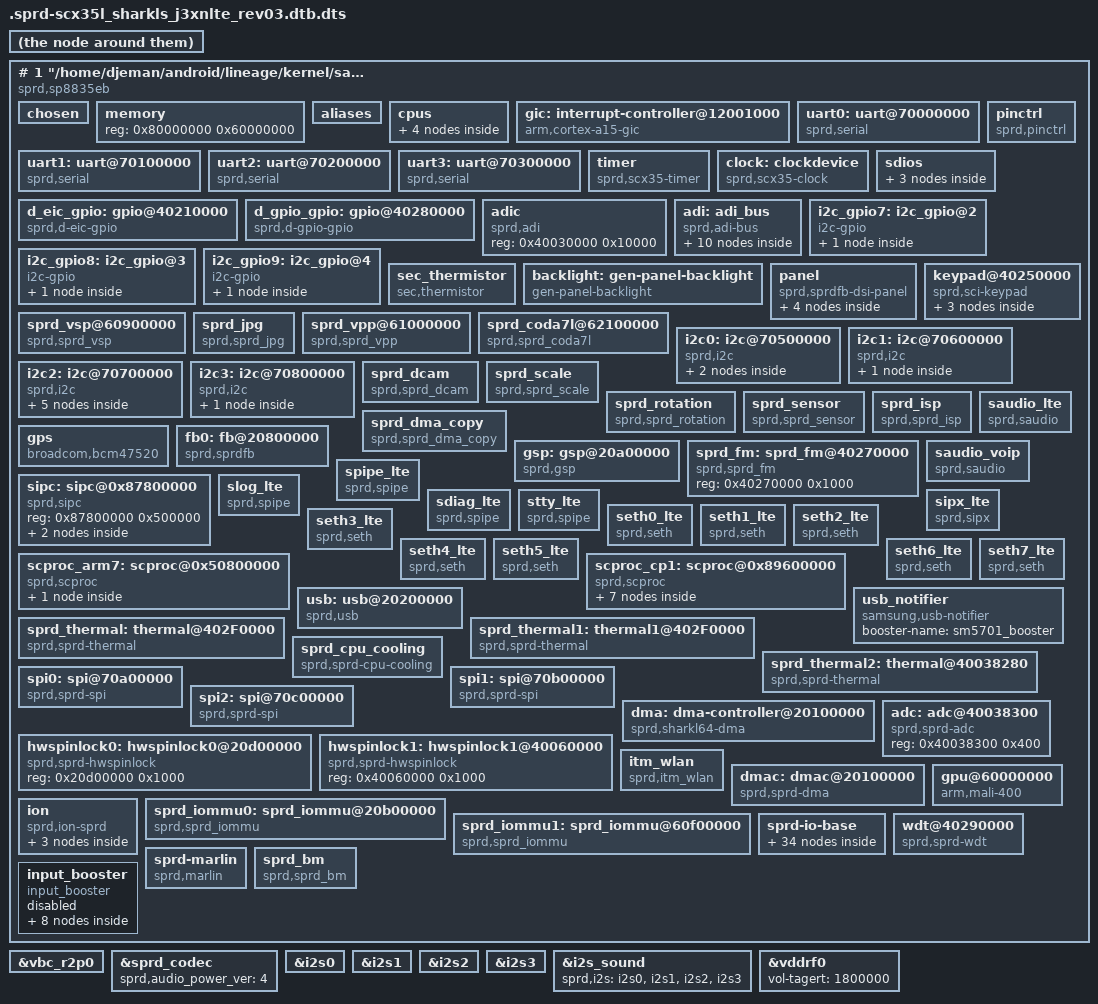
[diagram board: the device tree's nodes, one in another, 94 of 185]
# 1 "arch/arm/boot/dts/sprd-scx35l_sharkls_j3xnlte_rev03.dts"
# 1 "<command-line>"
# 1 "arch/arm/boot/dts/sprd-scx35l_sharkls_j3xnlte_rev03.dts"
# 9 "arch/arm/boot/dts/sprd-scx35l_sharkls_j3xnlte_rev03.dts"
/dts-v1/;


/memreserve/ 0x87800000 0x500000;


/memreserve/ 0x89600000 0x4280000;


/memreserve/ 0x9B23B000 0x3939000;

/memreserve/ 0x9EB74000 0xA8C000;


/memreserve/ 0x9F600000 0x708000;

/include/ "skeleton.dtsi"
/include/ "scx35l-sp9830iea-5m-clocks.dtsi"
/include/ "sc2723-regulators.dtsi"
/include/ "sprd-sound.dtsi"
/include/ "sprd-scx35l_batterydata_j3xlte_r00.dtsi"

# 1 "/home/djeman/android/lineage/kernel/samsung/j3xnlte/arch/arm/boot/dts/include/dt-bindings/gpio/gpio.h" 1
# 32 "arch/arm/boot/dts/sprd-scx35l_sharkls_j3xnlte_rev03.dts" 2
# 1 "/home/djeman/android/lineage/kernel/samsung/j3xnlte/arch/arm/boot/dts/include/dt-bindings/interrupt-controller/irq.h" 1
# 33 "arch/arm/boot/dts/sprd-scx35l_sharkls_j3xnlte_rev03.dts" 2

/ {
 model = "Spreadtrum SP8835EB board";
 compatible = "sprd,sp8835eb";
 sprd,sc-id = <9830 3 0x20000>;
 #address-cells = <1>;
 #size-cells = <1>;
 interrupt-parent = <&gic>;

 chosen {
  bootargs = "loglevel=1 init=/init root=/dev/ram0 rw";
  linux,initrd-start = <0x85500000>;
  linux,initrd-end = <0x855a3212>;
 };

 memory {
  device_type = "memory";
  reg = <0x80000000 0x60000000>;
 };

 aliases {
  serial0 = &uart0;
  serial1 = &uart1;
  serial2 = &uart2;
  serial3 = &uart3;
  i2c0 = &i2c0;
  i2c1 = &i2c1;
  i2c2 = &i2c2;
  i2c3 = &i2c3;
  lcd0 = &fb0;
  spi0 = &spi0;
  spi1 = &spi1;
  spi2 = &spi2;
  hwspinlock0 = &hwspinlock0;
  hwspinlock1 = &hwspinlock1;
  i2c_gpio7 = &i2c_gpio7;
  i2c_gpio8 = &i2c_gpio8;
  i2c_gpio9 = &i2c_gpio9;
 };

 cpus {
  #address-cells = <1>;
  #size-cells = <0>;

  cpu@f00 {
   device_type = "cpu";
   compatible = "arm,cortex-a7";
   reg = <0xf00>;
  };

  cpu@f01 {
   device_type = "cpu";
   compatible = "arm,cortex-a7";
   reg = <0xf01>;
  };

  cpu@f02 {
   device_type = "cpu";
   compatible = "arm,cortex-a7";
   reg = <0xf02>;
  };

  cpu@f03 {
   device_type = "cpu";
   compatible = "arm,cortex-a7";
   reg = <0xf03>;
  };
 };

 gic: interrupt-controller@12001000 {
  compatible = "arm,cortex-a15-gic", "arm,cortex-a9-gic";
  #interrupt-cells = <3>;
  #address-cells = <0>;
  interrupt-controller;
  reg = <0x12001000 0x1000>,
   <0x12002000 0x1000>;
 };

 uart0: uart@70000000 {
  compatible = "sprd,serial";
  interrupts = <0 2 0x0>;
  reg = <0x70000000 0x1000>;
  clock-names = "clk_uart0";
  clocks = <&clock 60>;
  sprdclk = <48000000>;
  sprdwaketype = "BT_RTS_HIGH_WHEN_SLEEP";
 };
 uart1: uart@70100000 {
  compatible = "sprd,serial";
  interrupts = <0 3 0x0>;
  reg = <0x70100000 0x1000>;
  clock-names = "clk_uart1";
  clocks = <&clock 61>;
  sprdclk = <26000000>;
  sprdwaketype = "BT_RTS_HIGH_WHEN_SLEEP";
 };
 uart2: uart@70200000 {
  compatible = "sprd,serial";
  interrupts = <0 4 0x0>;
  reg = <0x70200000 0x1000>;
  clock-names = "clk_uart2";
  clocks = <&clock 62>;
  sprdclk = <26000000>;
  sprdwaketype = "BT_RTS_HIGH_WHEN_SLEEP";
 };
 uart3: uart@70300000 {
  compatible = "sprd,serial";
  interrupts = <0 5 0x0>;
  reg = <0x70300000 0x1000>;
  clock-names = "clk_uart3";
  clocks = <&clock 63>;
  sprdclk = <26000000>;
  sprdwaketype = "BT_RTS_HIGH_WHEN_SLEEP";
 };

 timer {
  compatible = "sprd,scx35-timer";
  reg = <0x40230000 0x1000>,
   <0x40050000 0x1000>,
   <0x40220000 0x1000>,
   <0x40320000 0x1000>,
   <0x40330000 0x1000>;
  interrupts = <0 118 0x0>,
    <0 28 0x0>,
    <0 29 0x0>,
    <0 119 0x0>,
    <0 121 0x0>,
    <0 31 0x0>;
 };
 clock: clockdevice {
  compatible = "sprd,scx35-clock";
  #clock-cells = <1>;
 };
 d_eic_gpio: gpio@40210000 {
  compatible = "sprd,d-eic-gpio";
  reg = <0x40210000 0x1000>;
  gpio-controller;
  interrupt-controller;
  #interrupt-cells = <2>;
  #gpio-cells = <2>;
  gpiobase = <288>;
  ngpios = <16>;
  interrupts = <0 37 0x0>;
 };
 d_gpio_gpio: gpio@40280000 {
  compatible = "sprd,d-gpio-gpio";
  reg = <0x40280000 0x1000>;
  gpio-controller;
  interrupt-controller;
  #interrupt-cells = <2>;
  #gpio-cells = <2>;
  gpiobase = <0>;
  ngpios = <256>;
  interrupts = <0 35 0x0>;
 };

 pinctrl {
  compatible = "sprd,pinctrl";
  reg = <0x402a0000 0x1000>;
  pwr_domain = "vdd18",
   "vdd18",
   "vddsim0",
   "vddsim1",
   "vdd18",
   "vddsdcore",
   "vdd18";
  ctrl_desc = <0x10 0 1
   0x10 1 1
   0x10 2 1
   0x10 3 1
   0x10 4 1
   0x10 5 1
   0x10 6 1>;
 };

 sdios{
  #address-cells = <2>;
  #size-cells = <2>;
  ranges;
  sdio3: sdio@20600000{
   compatible = "sprd,sdhost-3.0";
   reg = <0 0x20600000 0 0x1000>;
   interrupts = <0 60 0x0>;
   sprd,name = "sdio_emmc";



   signal_default_Voltage = <1800000>;
   ocr_avail = <0x00040000>;
   clocks = <&clk_emmc>, <&clk_384m>;
   base_clk = <384000000>;
   caps = <0xC00F8D47>;
   caps2 = <0x202>;
   pm_caps = <0x4>;
   writeDelay = <0x34>;
   readPosDelay = <0x8>;
   readNegDelay = <0x8>;
  };

  sdio0: sdio@20300000{
   compatible = "sprd,sdhost-3.0";
   reg = <0 0x20300000 0 0x1000>;
   interrupts = <0 57 0x0>;
   sprd,name = "sdio_sd";
   detect_gpio = <144>;
   SD_Pwr_Name = "vddsdcore";

   signal_default_Voltage = <3000000>;
   ocr_avail = <0x00040000>;
   clocks = <&clk_sdio0>, <&clk_384m>;
   base_clk = <384000000>;
   caps = <0xC0000407>;
   caps2 = <0x200>;
   pm_caps = <0x4>;
   writeDelay = <0x3>;
   readPosDelay = <0x3>;
   readNegDelay = <0x3>;
  };


  sdio1: sdio@20400000{
   compatible = "sprd,sdhost-3.0";
   reg = <0 0x20400000 0 0x1000>;
   interrupts = <0 58 0x0>;
   sprd,name = "sdio_wifi";




   ocr_avail = <0x00360080>;
   clocks = <&clk_sdio1>, <&clk_76m8>;
   base_clk = <96000000>;
   caps = <0xC00FA407>;
   caps2 = <0x0>;
   pm_caps = <0x5>;
   writeDelay = <0x03>;
   readPosDelay = <0x03>;
   readNegDelay = <0x03>;
  };
 };

 adic:adic {
  compatible = "sprd,adi";
  reg = <0x40030000 0x10000>;
 };
 adi: adi_bus {
  compatible = "sprd,adi-bus";
  interrupts = <0 38 0x0>;
  reg = <0x40038000 0x1000>;
  interrupt-controller;
  sprd,irqnums = <11>;
  #interrupt-cells = <2>;
  #address-cells = <1>;
  #size-cells = <1>;
  ranges = <0x40 0x40038040 0x40>,
   <0x80 0x40038080 0x80>,
   <0x100 0x40038100 0x80>,
   <0x480 0x40038480 0x80>;
  watchdog@40{
   compatible = "sprd,watchdog";
   reg = <0x40 0x40>;
   interrupts = <3 0x0>;
  };
  rtc@80 {
   compatible = "sprd,rtc";
   reg = <0x80 0x80>;
   interrupts = <2 0x0>;
  };
  a_eic_gpio: gpio@100 {
   compatible = "sprd,a-eic-gpio";
   reg = <0x100 0x80>;
   gpio-controller;
   interrupt-controller;
   #interrupt-cells = <2>;
   #gpio-cells = <2>;
   gpiobase = <304>;
   ngpios = <16>;
   interrupt-parent = <&adi>;
   interrupts = <5 0x0>;
  };

  a_gpio_gpio: gpio@480 {
   compatible = "sprd,a-gpio-gpio";
   reg = <0X480 0x80>;
   gpio-controller;
   interrupt-controller;
   #interrupt-cells = <2>;
   #gpio-cells = <2>;
   gpiobase = <256>;
   ngpios = <32>;
   interrupt-parent = <&adi>;
   interrupts = <1 0x0>;
  };

  keyboard_backlight {
   compatible = "sprd,keyboard-backlight";
  };


  headset_sprd_sc2723 {
   compatible = "sprd,headset_sprd_sc2723";
   gpio_switch = <0>;
   gpio_detect = <312>;
   gpio_button = <307>;
   irq_trigger_level_detect = <1>;
   irq_trigger_level_button = <1>;
   adc_threshold_gnd_average = <400>;
   adc_threshold_left_average = <500>;
   adc_threshold_3pole_detect = <3269>;
   adc_threshold_4pole_detect = <3270>;
   irq_threshold_buttont = <4>;
   voltage_headmicbias = <3000000>;
   nbuttons = <4>;
   headset_buttons_media {
    adc_min = <0>;
    adc_max = <496>;
    code = <226>;
    type = <0>;
   };
   headset_buttons_voc_assist {
       adc_min = <497>;
       adc_max = <695>;
       code = <0x246>;
       type = <0>;
      };
   headset_buttons_up {
    adc_min = <696>;
    adc_max = <1199>;
    code = <115>;
    type = <0>;
   };
   headset_buttons_down {
    adc_min = <1200>;
    adc_max =<3000>;
    code = <114>;
    type = <0>;
   };
  };

 };

 i2c_gpio7: i2c_gpio@2 {
  compatible = "i2c-gpio";
  #address-cells = <1>;
  #size-cells = <0>;
  gpios = <&d_gpio_gpio 155 0
                        &d_gpio_gpio 154 0 >;
  i2c-gpio,delay-us = <10>;
  i2c-gpio,timeout-ms = <0>;

  sm5504@14 {
   compatible = "SiliconMitus,sm5504";
   reg = <0x14>;
   interrupt-parent = <&d_gpio_gpio>;
   sm5504,irq-gpio = <&d_gpio_gpio 52 0>;
  };
 };

 i2c_gpio8: i2c_gpio@3 {
  compatible = "i2c-gpio";
  #address-cells = <1>;
  #size-cells = <0>;
  gpios = <&d_gpio_gpio 53 0
     &d_gpio_gpio 55 0 >;
  i2c-gpio,delay-us = <10>;
  i2c-gpio,timeout-ms = <0>;
  status = "okay";

  coreriver@20 {
   compatible = "coreriver,coreriver-tkey";
   reg = <0x20>;
   interrupt-parent = <&d_gpio_gpio>;
   coreriver,irq-gpio = <&d_gpio_gpio 90 0>;
   coreriver,sda-gpio = <&d_gpio_gpio 53 0>;
   coreriver,scl-gpio = <&d_gpio_gpio 55 0>;
   coreriver,vcc_en-gpio = <&d_gpio_gpio 140 0>;
   coreriver,fw_name = "coreriver/j3xlte.fw";
   coreriver,ext_fw_name = "/sdcard/tc350k_j3xlte.bin";
   coreriver,sensing_ch_num = <4>;
   coreriver,tsk_ic_num = <1>;
   coreriver,firm-up;
  };
 };

 i2c_gpio9: i2c_gpio@4 {
  compatible = "i2c-gpio";
  #address-cells = <1>;
  #size-cells = <0>;
  gpios = <&d_gpio_gpio 8 0
    &d_gpio_gpio 10 0 >;
  i2c-gpio,delay-us = <10>;
  i2c-gpio,timeout-ms = <0>;

  cm36672p@60 {
   compatible = "cm36672p";
   reg = <0x60>;
   pinctrl-names = "default";
   interrupt-parent = <&d_gpio_gpio>;
   interrupts = <95 0>;
   cm36672p,vdd-supply = <&vdd28>;
   cm36672p,leden_gpio = <&d_gpio_gpio 141 0x00>;
   cm36672p,irq_gpio = <&d_gpio_gpio 95 0x00>;
   cm36672p,default_hi_thd = <18>;
   cm36672p,default_low_thd = <12>;
   cm36672p,cancel_hi_thd = <10>;
   cm36672p,cancel_low_thd = <7>;
   cm36672p,ps_duty = <2>;
   cm36672p,ps_it = <4>;
   cm36672p,led_current = <3>;
   cm36672p,default_trim = <3>;
  };
 };

 sec_thermistor {
  compatible = "sec,thermistor";
 };

 backlight: gen-panel-backlight {
  compatible = "gen-panel-backlight";
  backlight-name = "panel";
                backlight-brt-range = <
                        0 0
                        5 5
                        20 20
                        134 134
                        255 255
                        255 255
                >;
  backlight-brt-map = <

   0 0
   4 4 6 6
   7 7 8 8
   9 9 10 10
   11 11 12 12
   13 13 14 14
   15 15 16 16
   17 17 18 19
   19 20 20 21
   21 22 22 24
   23 25 24 27
   25 29 26 30
   27 32 28 34
   29 37 30 39
   31 41 33 44
   35 47 38 50
   40 53 41 56
   46 60 49 64
   52 68 56 72
   59 77 63 82
   67 87 71 93
   76 98 80 105
   86 111 91 119
   97 126 104 134
   110 143 118 152
   125 162 133 172
   142 183 150 195
   160 207 170 220
   181 234 193 249
   205 265 218 282
   230 300 242 316
   254 333 255 360
   255 500
  >;
                gen-panel-bl-hbm-en;
                gen-panel-bl-tune-en;
 };
 panel {
  compatible = "sprd,sprdfb-dsi-panel";
  pinctrl-names = "default";
  gen-panel = <&gen_panel>;
  gen-panel-backlight = <&backlight>;
  panel-ext-pin {
   panel-ext-pin-on-0 = <
    &panel_rst_n 0 10
    &panel_vci 1 10
   >;
   panel-ext-pin-on = <
    &panel_rst_n 1 10000
   >;
   panel-ext-pin-off = <
    &panel_rst_n 0 10
    &panel_vci 0 10
   >;
   panel_vci: panel-ext-pin-0 {
    pin-name = "panel_vci";
    pin-type = <1>;
    pin-supply = <&vddkpled>;
   };
   panel_rst_n: panel-ext-pin-1 {
    pin-name = "panel_rst_n";
    pin-type = <0>;
    pin-gpio = <&d_gpio_gpio 50 0>;
   };
  };
  gen_panel: gen-panel{};
 };

 keypad@40250000 {
  compatible = "sprd,sci-keypad";
  reg = <0X40250000 0x1000>;
  gpios = <&a_eic_gpio 2 0>,<&a_eic_gpio 10 0>;
  interrupts = <0 36 0x0>;
  sprd,keypad-num-rows = <2>;
  sprd,keypad-num-columns = <3>;
  sprd,keypad-rows-choose-hw = <0x30000>;
  sprd,keypad-cols-choose-hw = <0x700>;
  sprd,debounce_time = <5000>;
  linux,keypad-no-autorepeat;

  key_volume_up {
   keypad,row = <0>;
   keypad,column = <0>;
   linux,code = <115>;
  };

  key_volume_up1 {
   keypad,row = <0>;
   keypad,column = <1>;
   linux,code = <115>;
  };

  key_home {
   keypad,row = <0>;
   keypad,column = <2>;
   linux,code = <172>;
  };

         };

 sprd_vsp@60900000 {
  compatible = "sprd,sprd_vsp";
  reg = <0x60900000 0xc000>;
  interrupts = <0 43 0x0>;
  clock-names = "clk_mm_i", "clk_vsp";
  clocks = <&clk_mm>, <&clk_vsp>;
  version = <3>;
 };
 sprd_jpg {
  compatible = "sprd,sprd_jpg";
  reg = <0x60b00000 0x8000>;
  interrupts = <0 42 0x0>;
  clock-names = "clk_mm_i","clk_jpg";
  clocks = <&clk_mm>, <&clk_jpg>;
 };

  sprd_vpp@61000000{
                 compatible = "sprd,sprd_vpp";
                 reg = <0x61000000 0x4000>;
                 interrupts = <0 43 0x0>;
  clock-names = "clk_mm_i","clk_vpp";
  clocks = <&clk_mm>, <&clk_vpp>;
         };

  sprd_coda7l@62100000{
  compatible = "sprd,sprd_coda7l";
  reg = <0x62100000 0x4000>;
  interrupts = <0 43 0x0>;
  clock-names = "clk_mm_i","clk_coda7_axi","clk_coda7_cc","clk_coda7_apb";
  clocks = <&clk_mm>, <&clk_coda7_axi>, <&clk_coda7_cc>, <&clk_coda7_apb>;
  power-regs-info = <0x402b01a4 0 0x402b00c4 0x0000000f>;
         };
 i2c0: i2c@70500000 {
  compatible = "sprd,i2c";
  interrupts = <0 11 0x0>;
  reg = <0x70500000 0x1000>;
  #address-cells = <1>;
  #size-cells = <0>;
  sensor_main@0x3c {
   compatible = "sprd,sensor_main";
   reg = <0x3c>;
  };
  sensor_sub@0x21 {
   compatible = "sprd,sensor_sub";
   reg = <0x21>;
  };
 };
 i2c1: i2c@70600000 {
  compatible = "sprd,i2c";
  interrupts = <0 12 0x0>;
  reg = <0x70600000 0x1000>;
  #address-cells = <1>;
  #size-cells = <0>;
  ist30xxc@50 {
   compatible = "imagis,ist30xxc";
   reg = <0x50>;
   imagis,power-src = "vddsim2";
   gpios = <&d_gpio_gpio 142 0>;
   interrupt-parent = <&d_gpio_gpio>;
   interrupts = <142 0x1>;
   imagis,irq-flag = <0x2002>;
   imagis,irq-gpio = <&d_gpio_gpio 142 0x00>;
   imagis,avdd-volt = <3000000>;
   imagis,max-x = <720>;
   imagis,max-y = <1280>;
   imagis,max-w = <15>;
   imagis,chip-id = <0x038C>;

   imagis,chip-name = "IST3038C";
   imagis,chip-code = <3>;

   imagis,max-node = <576>;

   imagis,tkey = <1>;
   imagis,octa-hw = <1>;
  };
 };
 i2c2: i2c@70700000 {
  compatible = "sprd,i2c";
  interrupts = <0 13 0x0>;
  reg = <0x70700000 0x1000>;
  #address-cells = <1>;
  #size-cells = <0>;

  sm5701-i2c@49 {
   compatible = "sm,sm5701";
   reg = <0x49>;
   chargermfd {
    charger {
     compatible = "sm,sm5701-charger";
     chgen-gpio = <&d_gpio_gpio 215 0>;
     chgirq-gpio = <&d_gpio_gpio 92 0>;
    };
   };
   leds_sm5701 {
    compatible = "sm,leds_sm5701";
    flashen-gpio = <&d_gpio_gpio 54 0>;
    flashtorch-gpio = <&d_gpio_gpio 156 0>;
   };
  };

  bma_acc@18 {
   compatible = "bma2x2";
   reg = <0x18>;
   interrupt-parent = <&d_gpio_gpio>;
   interrupts = <135 0>;
   bma2x2,gpio_int1 = <&d_gpio_gpio 135 0x00>;
   bma2x2,accel_place = <3>;
  };
 };

 i2c3: i2c@70800000 {
  compatible = "sprd,i2c";
  interrupts = <0 14 0x0>;
  reg = <0x70800000 0x1000>;
  #address-cells = <1>;
  #size-cells = <0>;

  pn547@2B {
   compatible = "pn547";
   reg = <0x2B>;
   pinctrl-names = "default";
   interrupt-parent = <&d_gpio_gpio>;
   interrupts = <51 0>;
   pn547,firm-gpio = <&d_gpio_gpio 89 0x00>;
   pn547,ven-gpio = <&d_gpio_gpio 85 0x00>;
   pn547,irq-gpio = <&d_gpio_gpio 51 0x00>;
   pn547,ldo_flag = <0>;
   pn547,gpio_power;
   pn547,pvdd_en = <&d_gpio_gpio 88 0x00>;
  };
 };

 sprd_dcam {
  compatible = "sprd,sprd_dcam";
  interrupts = <0 45 0>;
  reg = <0x60800000 0x100000>;
  clock-names = "clk_mm_i","clk_dcam";
  clocks = <&clk_mm>, <&clk_dcam>;
 };
 sprd_scale {
  compatible = "sprd,sprd_scale";
 };
 sprd_rotation {
  compatible = "sprd,sprd_rotation";
 };
 sprd_sensor {
  compatible = "sprd,sprd_sensor";
  reg = <0x60c00000 0x100000>;
  gpios = <&d_gpio_gpio 44 0
  &d_gpio_gpio 0 0
  &d_gpio_gpio 45 0
  &d_gpio_gpio 0 0
  &d_gpio_gpio 134 0
  &d_gpio_gpio 134 0
  &d_gpio_gpio 0 0
  &d_gpio_gpio 0 0
  &d_gpio_gpio 0 0
  &d_gpio_gpio 0 0
  &d_gpio_gpio 0 0
  &d_gpio_gpio 0 0
  &d_gpio_gpio 0 0
  &d_gpio_gpio 0 0
  &d_gpio_gpio 0 0
  &d_gpio_gpio 0 0
  &d_gpio_gpio 0 0
  &d_gpio_gpio 0 0
  &d_gpio_gpio 0 0
  &d_gpio_gpio 0 0>;
  vdds = "vddcammot",
   "vddcama",
   "vddcamd",
   "vddcamd",
   "vddcammot",
   "vddcama",
   "vddcamd",
   "vddcamd";
  clock-names ="clk_mm_i","clk_sensor","clk_ccir","clk_dcam","clk_dcam_mipi";
  clocks = <&clk_mm>,<&clk_sensor>,<&clk_ccir>,<&clk_dcam>,<&clk_dcam_mipi>;
 };
 sprd_isp {
  compatible = "sprd,sprd_isp";
  reg = <0x60a00000 0x100000>;
  clock-names = "clk_mm_i","clk_isp";
  clocks = <&clk_mm>, <&clk_isp>;
 };
 sprd_dma_copy {
  compatible = "sprd,sprd_dma_copy";
 };

 gps {
  compatible = "broadcom,bcm47520";
  gps-pwr-en = <&d_gpio_gpio 11 0>;
  gps-regulator = "vddcamio";
  tcxo-regulator = "vddsdio";
  tcxo-regulator-volt = <3300000>;
 };

 fb0: fb@20800000 {
  compatible = "sprd,sprdfb";
  reg = <0x20800000 0x1000>,<0x21800000 0x1000>;
  interrupts = <0 46 0x0>,<0 48 0x0>, <0 49 0x0>;
  clock-names = "dispc_clk_parent", "dispc_dbi_clk_parent", "dispc_dpi_clk_parent", "dispc_emc_clk_parent", "dispc_clk", "dispc_dbi_clk", "dispc_dpi_clk", "dispc_emc_clk", "fb_spi_clock", "fb_spi_clock_parent";
  clocks = <&clk_256m>, <&clk_256m>, <&clk_384m>, <&clk_aon_apb>, <&clk_dispc0>, <&clk_dispc0_dbi>, <&clk_dispc0_dpi>, <&clk_disp_emc>, <&clk_spi2>, <&ext_26m>;
  clock-src = <256000000 256000000 384000000>;
  dpi_clk_div = <7>;
  sprd,fb_use_reservemem;
  sprd,fb_mem = <0x9EB74000 0xA8C000>;
 };

 gsp:gsp@20a00000 {
  compatible = "sprd,gsp";
  reg = <0x20a00000 0x1000>;
  interrupts = <0 51 0x0>;
  clock-names = "clk_gsp", "clk_gsp_emc", "clk_gsp_parent", "clk_aon_apb";
  clocks = <&clk_gsp>, <&clk_gsp_emc>, <&clk_256m>, <&clk_aon_apb>;
  gsp_mmu_ctrl_base = <0x20b08000>;
 };

 sprd_fm: sprd_fm@40270000{
  compatible = "sprd,sprd_fm";
  reg = <0x40270000 0x1000>;
 };




 sipc: sipc@0x87800000 {
  compatible = "sprd,sipc";
  reg = <0x87800000 0x500000>;

  #address-cells = <1>;
  #size-cells = <1>;
  ranges = <0x09600000 0x89600000 0x4280000>,
    <0x07800000 0x87800000 0x500000>,
    <0x01440000 0x8AA40000 0x1000>,
    <0x5000c000 0x5000c000 0x1000>;

  sipc_lte@0x09600000 {
   sprd,name = "sipc-lte";
   sprd,dst = <5>;

   mailbox,core = <7>;
   reg = <0x09600000 0x4280000> ,
    <0x07800000 0x500000>,
    <0x01440000 0x1000>;
          };

  sipc_pmsys@0x5000c000 {
   sprd,name = "sipc-pmsys";
                sprd,dst = <6>;

                mailbox,core = <1>;
   reg = <0x5000c000 0x1000>;
  };
 };

 saudio_lte{
  compatible = "sprd,saudio";
  sprd,saudio-dst-id = <5>;
  sprd,ctrl_channel = <10>;
  sprd,playback_channel = <11>;
  sprd,capture_channel = <12>;
  sprd,monitor_channel = <13>;
  sprd,saudio-names = "saudiolte";
 };
 saudio_voip{
  compatible = "sprd,saudio";
  sprd,saudio-dst-id = <5>;
  sprd,ctrl_channel = <14>;
  sprd,playback_channel = <15>;
  sprd,capture_channel = <16>;
  sprd,monitor_channel = <17>;
  sprd,saudio-names = "saudiovoip";
 };



 spipe_lte {
  compatible = "sprd,spipe";
  sprd,name = "spipe_lte";
  sprd,dst = <5>;
  sprd,channel = <4>;
  sprd,ringnr = <11>;
  sprd,size-rxbuf = <0x1000>;
  sprd,size-txbuf = <0x1000>;
 };

 slog_lte {
  compatible = "sprd,spipe";
  sprd,name = "slog_lte";
  sprd,dst = <5>;
  sprd,channel = <5>;
  sprd,ringnr = <1>;
  sprd,size-rxbuf = <0x40000>;
  sprd,size-txbuf = <0x8000>;
 };
        sdiag_lte {
                compatible = "sprd,spipe";
                sprd,name = "sdiag_lte";
                sprd,dst = <5>;
                sprd,channel = <21>;
                sprd,ringnr = <1>;
                sprd,size-rxbuf = <0x40000>;
                sprd,size-txbuf = <0x8000>;
        };

 stty_lte {
  compatible = "sprd,spipe";
  sprd,name = "stty_lte";
  sprd,dst = <5>;
  sprd,channel = <6>;
  sprd,ringnr = <32>;
  sprd,size-rxbuf = <0x0800>;
  sprd,size-txbuf = <0x0800>;
 };
 sipx_lte {
  compatible = "sprd,sipx";
  sprd,name = "sipx_lte";
  sprd,dst = <5>;
  sprd,dl-pool = <1024>;
  sprd,dl-ack-pool = <512>;
  sprd,ul-pool = <1024>;
  sprd,ul-ack-pool = <1024>;
 };

 seth0_lte {
  compatible = "sprd,seth";
  sprd,name = "rmnet0";
  sprd,dst = <5>;
  sprd,channel = <7>;
  sprd,blknum = <512>;
  sprd,poolsize = <16>;
 };

 seth1_lte {
  compatible = "sprd,seth";
  sprd,name = "rmnet1";
  sprd,dst = <5>;
  sprd,channel = <8>;
  sprd,blknum = <512>;
  sprd,poolsize = <16>;
 };

 seth2_lte {
  compatible = "sprd,seth";
  sprd,name = "rmnet2";
  sprd,dst = <5>;
  sprd,channel = <9>;
  sprd,blknum = <512>;
  sprd,poolsize = <16>;
 };

 seth3_lte {
  compatible = "sprd,seth";
  sprd,name = "rmnet3";
  sprd,dst = <5>;
  sprd,channel = <18>;
  sprd,blknum = <512>;
  sprd,poolsize = <16>;
 };

 seth4_lte {
  compatible = "sprd,seth";
  sprd,name = "rmnet4";
  sprd,dst = <5>;
  sprd,channel = <19>;
  sprd,blknum = <512>;
  sprd,poolsize = <16>;
 };

 seth5_lte {
  compatible = "sprd,seth";
  sprd,name = "rmnet5";
  sprd,dst = <5>;
  sprd,channel = <20>;
  sprd,blknum = <512>;
  sprd,poolsize = <16>;
 };

 seth6_lte {
  compatible = "sprd,seth";
  sprd,name = "rmnet6";
  sprd,dst = <5>;
  sprd,channel = <24>;
  sprd,blknum = <512>;
  sprd,poolsize = <16>;
 };

 seth7_lte {
  compatible = "sprd,seth";
  sprd,name = "rmnet7";
  sprd,dst = <5>;
  sprd,channel = <25>;
  sprd,blknum = <512>;
  sprd,poolsize = <16>;
 };

 scproc_arm7: scproc@0x50800000 {
  compatible = "sprd,scproc";
  sprd,name = "cppmic";
  sprd,ctrl-reg = <0x114 0xff 0xb0 0xff>;
  sprd,ctrl-mask = <0x01 0xf0000 0x100 0xf0000>;
  sprd,iram-data = <0xe59f0000 0xe12fff10 0x0>;
  reg = <0x50800000 0x8000>,
   <0x50800000 0x0>,
   <0x402e0000 0x400>,
                        <0x402e0000 0x400>,
                        <0x402b0000 0x100>,
   <0x402b0000 0x100>;
                interrupts = <0 0x7c 0x0>;
  #address-cells = <1>;
  #size-cells = <1>;

  ranges = <0x0 0x50800000 0x8000>;
  modem@0x0 {
   cproc,name = "modem";
   reg = <0x0 0x5400>;
  };
 };

 scproc_cp1: scproc@0x89600000 {
  compatible = "sprd,scproc";
  sprd,name = "cptl";
  sprd,ctrl-reg = <0x0c 0xcc 0xb0 0x78>;
  sprd,ctrl-mask = <0x100000 0x140000 0x02 0x1>;
  sprd,iram-data = <0xe59f0000 0xe12fff10 0x8AB88000>;
  reg = <0x89600000 0x4280000>,
   <0x50001000 0x0c>,
   <0x402e0000 0x100>,
                        <0x402b0000 0x100>,
                        <0x402b0000 0x100>,
   <0x402b0000 0x100>,
   <0x8AA41000 0x800>;
  interrupts = <0 84 0x0>;
  #address-cells = <1>;
  #size-cells = <1>;

  ranges = <0x1588000 0x8AB88000 0x00C30000>,
    <0x0020000 0x89620000 0x002E0000>,
                         <0x0300000 0x89900000 0x1C0000>,
    <0x3B00000 0x8D100000 0x200000>,
    <0x1441800 0x8AA41800 0x800>,
    <0x1442000 0x8AA42000 0x90000>,
    <0x14D2000 0x8AAD2000 0xB4000>;
  modem@0x1588000 {
   cproc,name = "modem";
   reg = <0x01588000 0x00C30000>;
  };
  dsp@0x20000 {
   cproc,name = "tgdsp";
   reg = <0x20000 0x002e0000>;
  };
  dsp@0x300000 {
   cproc,name = "ldsp";
   reg = <0x300000 0x1c0000>;
  };
  modem@0x3B00000 {
   cproc,name = "warm";
   reg = <0x3B00000 0x200000>;
  };
  cpcmdline@0x1441800 {
   cproc,name = "cpcmdline";
   reg = <0x1441800 0x800>;
  };
  fixnv@0x1442000 {
   cproc,name = "fixnv";
   reg = <0x1442000 0x90000>;
  };
  runnv@0x14D2000 {
   cproc,name = "runnv";
   reg = <0x14D2000 0xB4000>;
  };
 };

 usb: usb@20200000 {
  compatible = "sprd,usb";
  interrupts = <0 55 0x0>;
  ngpios = <1>;
  gpios = <&a_eic_gpio 0 0>;
  reg = <0x20200000 0x1000>;
  tune_value = <0x078e33>;
  usb-supply = <&vddusb>;
  #address-cells = <1>;
  #size-cells = <0>;
 };

 usb_notifier {
  compatible = "samsung,usb-notifier";
  booster-name = "sm5701_booster";
 };

 sprd_thermal: thermal@402F0000{
  compatible = "sprd,sprd-thermal";
  id = <0>;
  interrupts = <0 26 0x0>;
  reg = <0x402f0000 0x1000>;
  trip_points_active = <31 56 60 90 110>;
  trip_points_lowoff = <0 29 46 50 80>;
  trip_points_critical = <110>;
  trip_num = <6>;
 };
 sprd_thermal1:thermal1@402F0000 {
  compatible = "sprd,sprd-thermal";
  id = <1>;
  interrupts = <0 26 0x0>;
  reg = <0x402F0000 0x1000>;
  trip_points_active = <110>;
  trip_points_lowoff = <90>;
  trip_points_critical = <110>;
  trip_num = <2>;
 };
 sprd_thermal2: thermal@40038280{
  compatible = "sprd,sprd-thermal";
  id = <2>;
  interrupt-parent = <&adi>;
  interrupts = <9 0x0>;
  reg = <0x40038280 0x1000>;
  trip_points_active = <110>;
  trip_points_lowoff = <90>;
  trip_points_critical = <110>;
  trip_num = <2>;
 };
 sprd_cpu_cooling{
  compatible = "sprd,sprd-cpu-cooling";
  id = <0>;
  max_freq = <1350000 1500000 1350000 900000 768000>;
  max_core = <4 4 4 4 1>;
  state_num = <5>;
  vddarm_update0 = <0 1350000 1050000>;
  vddarm_update1 = <1 1350000 1000000>;
  vddarm_nr = <2 3 3>;
 };
 spi0: spi@70a00000 {
  compatible = "sprd,sprd-spi";
  interrupts = <0 7 0x0>;
  reg = <0x70a00000 0x1000>;
  clock-names = "clk_spi0";
  #address-cells = <1>;
  #size-cells = <0>;
 };
 spi1: spi@70b00000 {
  compatible = "sprd,sprd-spi";
  interrupts = <0 8 0x0>;
  reg = <0x70b00000 0x1000>;
  clock-names = "clk_spi1";
  #address-cells = <1>;
  #size-cells = <0>;
 };
 spi2: spi@70c00000 {
  compatible = "sprd,sprd-spi";
  interrupts = <0 9 0x0>;
  reg = <0x70c00000 0x1000>;
  clock-names = "clk_spi2";
  #address-cells = <1>;
  #size-cells = <0>;
 };
 dma: dma-controller@20100000 {
  compatible = "sprd,sharkl64-dma";
  #dma-cells = <1>;
  #dma-channels = <64>;
  aon_offset = <32>;
  reg = <0 0x20100000 0 0x4000>,
   <0 0x40100000 0 0x4000>;
  interrupts = <0 50 0x0>,
    <0 70 0x0>;
 };
 adc: adc@40038300 {
  compatible = "sprd,sprd-adc";
  reg = <0x40038300 0x400>;
 };
 hwspinlock0: hwspinlock0@20d00000 {
  compatible = "sprd,sprd-hwspinlock";
  reg = <0x20d00000 0x1000>;
 };
 hwspinlock1: hwspinlock1@40060000 {
  compatible = "sprd,sprd-hwspinlock";
  reg = <0x40060000 0x1000>;
 };
 itm_wlan{
  compatible = "sprd,itm_wlan";
 };
 dmac: dmac@20100000 {
  compatible = "sprd,sprd-dma";
  interrupts = <0 50 0x0>;
  reg = <0 0x20100000 0 0x4000>;
 };
 gpu@60000000 {
  compatible = "arm,mali-400", "arm,mali-utgard";
  reg = <0x60000000 0x10000>;
  interrupts = <0 39 0>, <0 39 0>, <0 39 0>, <0 39 0>, <0 39 0>, <0 39 0>, <0 39 0>;
  interrupt-names = "IRQGP", "IRQGPMMU", "IRQPP0", "IRQPPMMU0", "IRQPP1", "IRQPPMMU1", "IRQPMU";

  pmu_domain_config = <0x1000 0x1000 0x1000 0x0 0x0 0x0 0x0 0x0 0x0 0x1000 0x0 0x0>;
  pmu_switch_delay = <0xffff>;

  clocks = <&clk_gpu_axi>,<&clk_gpu>,<&clk_153m6>,<&clk_192m>,<&clk_256m>,<&clk_307m2>,<&clk_384m>,<&clk_512m>;
  clock-names = "clk_gpu_axi","clk_gpu","clk_153m6","clk_192m","clk_256m","clk_307m2","clk_384m","clk_512m";

  freq-list-len = <4>;
  freq-lists = <153600 2 1>, <256000 4 1>, <384000 6 1>, <512000 7 1>;
  freq-default = <1>;
  freq-9 = <2>;
  freq-8 = <1>;
  freq-7 = <0>;
  freq-5 = <0>;
  freq-range-max = <3>;
  freq-range-min = <0>;
 };
 ion {
  compatible = "sprd,ion-sprd";
  #address-cells = <1>;
  #size-cells = <0>;
  sprd,ion-heap@1 {
   reg = <1>;
   reg-names = "ion_heap_system";
   sprd,ion-heap-type = <0>;
   sprd,ion-heap-mem = <0x0 0x0>;
  };

  sprd,ion-heap@2 {
   reg = <2>;
   reg-names = "ion_heap_carveout_mm";
   sprd,ion-heap-type = <2>;
   sprd,ion-heap-mem = <0x9B23B000 0x3939000>;
  };

  sprd,ion-heap@3 {
   reg = <3>;
   reg-names = "ion_heap_carveout_overlay";
   sprd,ion-heap-type = <2>;
   sprd,ion-heap-mem = <0x9F600000 0x708000>;
  };
 };
 sprd_iommu0:sprd_iommu@20b00000 {
  compatible = "sprd,sprd_iommu";
  func-name = "sprd_iommu_gsp";
  reg = <0x10000000 0x2000000>,
   <0x20b00000 0x8000>,
   <0x20b08000 0x8000>;
  reg_name = "iova","pgt","ctrl_reg";
  clock-names = "clk_gsp_emc","clk_153m6","clk_gsp";
  clocks = <&clk_gsp_emc>, <&clk_153m6>,<&clk_gsp>;
  status = "ok";
 };
 sprd_iommu1:sprd_iommu@60f00000 {
  compatible = "sprd,sprd_iommu";
  func-name = "sprd_iommu_mm";
  reg = <0x20000000 0x8000000>,
   <0x60f00000 0x20000>,
   <0x60f20000 0x2000>;
  reg_name = "iova","pgt","ctrl_reg";
  clock-names = "clk_mmu","clk_mm_i";
  clocks = <&clk_mmu>,<&clk_mm>;
  status = "ok";
 };
 sprd-io-base {
  #address-cells = <1>;
  #size-cells = <1>;
  ranges = <0 0 0x80000000>;
  ahb {
   compatible = "sprd,ahb";
   reg = <0x20e00000 0x10000>;
  };
  hwlock0 {
   compatible = "sprd,hwlock0";
   reg = <0x20d00000 0x1000>;
  };
  aonapb {
   compatible = "sprd,aonapb";
   reg = <0x402e0000 0x10000>;
  };
  apbreg {
   compatible = "sprd,apbreg";
   reg = <0x71300000 0x10000>;
  };
  pmu {
   compatible = "sprd,pmu";
   reg = <0x402b0000 0x10000>;
  };
  mmahb {
   compatible = "sprd,mmahb";
   reg = <0x60d00000 0x4000>;
  };
  mmckg {
   compatible = "sprd,mmckg";
   reg = <0x60e00000 0x1000>;
  };
  codecahb {
   compatible = "sprd,codecahb";
   reg = <0x62000000 0x1000>;
  };
  adislave {
   compatible = "sprd,adislave";
   reg = <0x40038000 0x1000>;
  };
  gpuapb {
   compatible = "sprd,gpuapb";
   reg = <0x60100000 0x1000>;
  };
  apbckg {
   compatible = "sprd,apbckg";
   reg = <0x21500000 0x1000>;
  };
  aonckg {
   compatible = "sprd,aonckg";
   reg = <0x402d0000 0x1000>;
  };
  gpuckg {
   compatible = "sprd,gpuckg";
   reg = <0x60200000 0x1000>;
  };
  core {
   compatible = "sprd,core";
   reg = <0x12000000 0x10000>;
  };
  int {
   compatible = "sprd,int";
   reg = <0x40200000 0x1000>;
  };
  intc0 {
   compatible = "sprd,intc0";
   reg = <0x71400000 0x1000>;
  };
  intc1 {
   compatible = "sprd,intc1";
   reg = <0x71500000 0x1000>;
  };
  intc2 {
   compatible = "sprd,intc2";
   reg = <0x71600000 0x1000>;
  };
  intc3 {
   compatible = "sprd,intc3";
   reg = <0x71700000 0x1000>;
  };
  send_mbox {
   compatible = "sprd,send_mbox";
   reg = <0x400a0000 0x1000>;
  };
  recv_mbox {
   compatible = "sprd,recv_mbox";
   reg = <0x400a8000 0x1000>;
  };
  uidefuse {
   compatible = "sprd,uidefuse";
   reg = <0x40240000 0x1000>;
  };
  isp {
   compatible = "sprd,isp";
   reg = <0x60a00000 0x8000>;
  };
  ca7wdg {
   compatible = "sprd,ca7wdg";
   reg = <0x40310000 0x1000>;
  };
  csi2 {
   compatible = "sprd,csi2";
   reg = <0x60c00000 0x1000>;
  };
  wdg {
   compatible = "sprd,wdg";
   reg = <0x40290000 0x1000>;
  };
  ipi {
   compatible = "sprd,ipi";
   reg = <0x402c0000 0x1000>;
  };
  dcam {
   compatible = "sprd,dcam";
   reg = <0x60800000 0x10000>;
  };
  syscnt {
   compatible = "sprd,syscnt";
   reg = <0x40230000 0x1000>;
  };
  dma0 {
   compatible = "sprd,dma0";
   reg = <0x20100000 0x4000>;
  };
  pub {
   compatible = "sprd,pub";
   reg = <0x30020000 0x10000>;
  };
  pin {
   compatible = "sprd,pin";
   reg = <0x402a0000 0x1000>;
  };
  mailbox {
   compatible = "sprd,mailbox";
   reg = <0x400a0000 0x10000>;
  };
  axibm0 {
   compatible = "sprd,axibm0";
   reg = <0 0x30040000 0 0x20000>;
   interrupts = <0 86 0x0>;
  };
 };
 wdt@40290000 {
  compatible = "sprd,sprd-wdt";
  reg = <0x40290000 0x1000>,
   <0x40310000 0x1000>;
  interrupts = <0 124 0x0>;
 };
 sprd-marlin {
  compatible = "sprd,marlin";
  gpios = <&d_gpio_gpio 97 0
    &d_gpio_gpio 132 0
    &d_gpio_gpio 133 0
    &d_gpio_gpio 30 0
    &d_gpio_gpio 130 0>;
  cp-rfctl-offset = <0x94>;
  vdd-download = "vddcon";
  vdd-pa = "vddwifipa";
  clk-name = "clk_aux0";
  sdhci-name = "sdio_wifi";
 };
 sprd_bm {
  compatible = "sprd,sprd_bm";
  reg = <0x30040000 0xA0000>,
      <0x20F00000 0x300000>;
  interrupts = <0 86 0x0>;
  sprd,bm_status = <1>;
  sprd,bm_count = <10 11>;
  sprd,cpu_chn = <0 1>;
  sprd,disp_chn = <1 1>;
  sprd,gpu_chn = <2 1>;
  sprd,ap_zip_chn = <3 1>;
  sprd,mm_chn = <4 1>;
  sprd,cp0_arm0_1_chn = <5 1>;
  sprd,cp0_dsp_chn = <6 0>;
  sprd,cp1_lte_chn = <7 1>;
  sprd,cp1_dsp_chn = <8 1>;
  sprd,cp1_arm_chn = <9 1>;
  sprd,ap_dap_chn = <0 0>;
  sprd,ap_cpu_chn = <0 1>;
  sprd,ap_dma_w_chn = <0 2>;
  sprd,ap_dma_r_chn = <0 3>;
  sprd,ap_sdio_0_chn = <1 0>;
  sprd,ap_sdio_1_chn = <1 1>;
  sprd,ap_sdio_2_chn = <1 2>;
  sprd,ap_emmc_chn = <1 3>;
  sprd,ap_nandc_chn = <2 0>;
  sprd,ap_otg_chn = <2 1>;
  sprd,ap_hsic_chn = <2 2>;
 };


 input_booster {
  status = "disabled";
  compatible = "input_booster";
  #address-cells = <1>;
  #size-cells = <0>;

  booster_key@1 {
   input_booster,label = "KEY";
   input_booster,type = <0>;

   input_booster,levels = <1>;



   input_booster,cpu_freqs = <1350000>;
   input_booster,core_num_lock = <2>;


   input_booster,head_times = <200>;
   input_booster,tail_times = <0>;

  };
  booster_key@2 {
   input_booster,label = "TOUCHKEY";
   input_booster,type = <1>;

   input_booster,levels = <1>;



   input_booster,cpu_freqs = <900000>;
   input_booster,core_num_lock = <2>;


   input_booster,head_times = <0>;
   input_booster,tail_times = <300>;
  };
  booster_key@3 {
   input_booster,label = "TOUCH";
   input_booster,type = <2>;

   input_booster,levels = <1 2 3>;



   input_booster,cpu_freqs = <1350000 1350000 900000>;
   input_booster,core_num_lock = <2>;


   input_booster,head_times = <200 200 0>;
   input_booster,tail_times = <0 0 300>;
  };
  booster_key@4 {
   input_booster,label = "MULTITOUCH";
   input_booster,type = <3>;

   input_booster,levels = <1 2>;



   input_booster,cpu_freqs = <1500000 768000>;
   input_booster,core_num_lock = <2>;


   input_booster,head_times = <1000 0>;
   input_booster,tail_times = <0 500>;
  };
  booster_key@5 {
   input_booster,label = "KEYBOARD";
   input_booster,type = <4>;

   input_booster,levels = <1 2>;



   input_booster,cpu_freqs = <1350000 1350000>;
   input_booster,core_num_lock = <2>;


   input_booster,head_times = <200 200>;
   input_booster,tail_times = <0 0>;
  };
  booster_key@6 {
   input_booster,label = "MOUSE";
   input_booster,type = <5>;

   input_booster,levels = <1 2>;



   input_booster,cpu_freqs = <1350000 900000>;
   input_booster,core_num_lock = <2>;


   input_booster,head_times = <200 0>;
   input_booster,tail_times = <0 300>;
  };
  booster_key@7 {
   input_booster,label = "MOUSE WHEEL";
   input_booster,type = <6>;

   input_booster,levels = <1 2>;



   input_booster,cpu_freqs = <1350000 0>;
   input_booster,core_num_lock = <2>;


   input_booster,head_times = <200 0>;
   input_booster,tail_times = <0 0>;
  };
  booster_key@8 {
   input_booster,label = "PEN HOVER";
   input_booster,type = <7>;

   input_booster,levels = <1 2>;



   input_booster,cpu_freqs = <1350000 900000>;
   input_booster,core_num_lock = <2>;


   input_booster,head_times = <200 0>;
   input_booster,tail_times = <0 300>;
  };
 };
};

/include/ "sprd-dsi-panel-dsi_s6e8aa5x01.dtsi"

&vbc_r2p0 {
 status = "okay";
};

&sprd_codec {
 status = "okay";
 sprd,audio_power_ver = <4>;
};

&i2s0 {
 sprd,config_type = "pcm";
 sprd,slave_timeout = <0xF11>;
 sprd,_hw_port = <0>;
 sprd,fs = <8000>;
 sprd,bus_type = <1>;
 sprd,rtx_mode = <3>;
 sprd,byte_per_chan = <1>;
 sprd,slave_mode = <0>;
 sprd,lsb = <0>;
 sprd,lrck = <0>;
 sprd,low_for_left = <1>;
 sprd,clk_inv = <0>;
 sprd,pcm_short_frame = <1>;
 sprd,pcm_slot = <0x1>;
 sprd,pcm_cycle = <1>;
 sprd,tx_watermark = <12>;
 sprd,rx_watermark = <20>;
 status = "okay";
};

&i2s1 {
 status = "okay";
};

&i2s2 {
 status = "okay";
};

&i2s3 {
 status = "okay";
};

&i2s_sound {
 sprd,i2s = <&i2s0>, <&i2s1>, <&i2s2>, <&i2s3>;
};
&vddrf0{

  vol-tagert = <1800000>;

};
